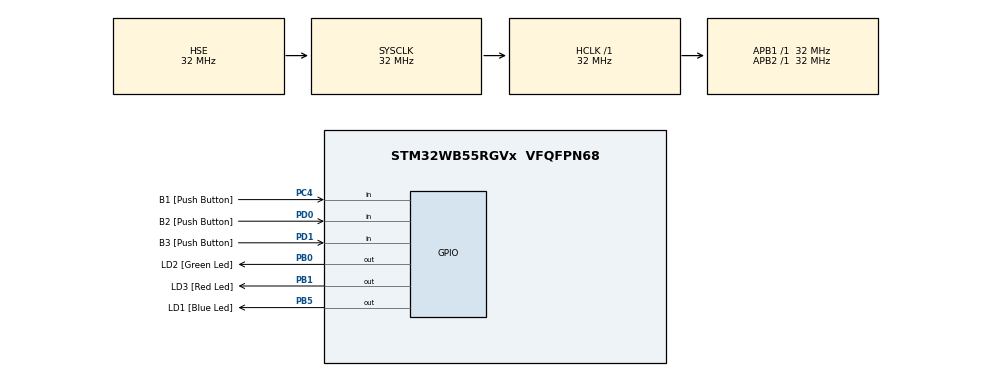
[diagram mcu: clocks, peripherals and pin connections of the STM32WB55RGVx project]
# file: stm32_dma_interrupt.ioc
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Dma.MEMTOMEM.0.Direction=DMA_MEMORY_TO_MEMORY
Dma.MEMTOMEM.0.EventEnable=DISABLE
Dma.MEMTOMEM.0.Instance=DMA1_Channel1
Dma.MEMTOMEM.0.MemDataAlignment=DMA_MDATAALIGN_BYTE
Dma.MEMTOMEM.0.MemInc=DMA_MINC_DISABLE
Dma.MEMTOMEM.0.Mode=DMA_NORMAL
Dma.MEMTOMEM.0.PeriphDataAlignment=DMA_PDATAALIGN_BYTE
Dma.MEMTOMEM.0.PeriphInc=DMA_PINC_DISABLE
Dma.MEMTOMEM.0.Polarity=HAL_DMAMUX_REQ_GEN_RISING
Dma.MEMTOMEM.0.Priority=DMA_PRIORITY_LOW
Dma.MEMTOMEM.0.RequestNumber=1
Dma.MEMTOMEM.0.SignalID=NONE
Dma.MEMTOMEM.0.SyncEnable=DISABLE
Dma.MEMTOMEM.0.SyncPolarity=HAL_DMAMUX_SYNC_NO_EVENT
Dma.MEMTOMEM.0.SyncRequestNumber=1
Dma.MEMTOMEM.0.SyncSignalID=NONE
Dma.Request0=MEMTOMEM
Mcu.Family=STM32WB
Mcu.Name=STM32WB55RGVx
Mcu.Package=VFQFPN68
NVIC.DMA1_Channel1_IRQn=true\:0\:0\:false\:false\:true\:true\:true\:true
NVIC.PriorityGroup=NVIC_PRIORITYGROUP_4
NVIC.RCC_IRQn=true\:0\:0\:false\:false\:true\:true\:false\:true
OSC_IN.Mode=HSE-External-Oscillator
OSC_IN.Signal=RCC_OSC_IN
OSC_OUT.Mode=HSE-External-Oscillator
OSC_OUT.Signal=RCC_OSC_OUT
PA11.Signal=USB_DM
PA12.Signal=USB_DP
PA13.GPIO_Label=JTMS
PA13.Signal=SYS_JTMS-SWDIO
PA14.GPIO_Label=JTCK
PA14.Signal=SYS_JTCK-SWCLK
PB0.GPIO_Label=LD2 [Green Led]
PB0.Signal=GPIO_Output
PB1.GPIO_Label=LD3 [Red Led]
PB1.Signal=GPIO_Output
PB3.GPIO_Label=JTDO
PB3.Signal=SYS_JTDO-SWO
PB5.GPIO_Label=LD1 [Blue Led]
PB5.Signal=GPIO_Output
PB6.GPIO_Label=STLINK_RX
PB6.Signal=USART1_TX
PB7.GPIO_Label=STLINK_TX
PB7.Signal=USART1_RX
PC13.Signal=SYS_WKUP2
PC14-OSC32_IN.Mode=LSE-External-Oscillator
PC14-OSC32_IN.Signal=RCC_OSC32_IN
PC15-OSC32_OUT.Mode=LSE-External-Oscillator
PC15-OSC32_OUT.Signal=RCC_OSC32_OUT
PC4.GPIO_Label=B1 [Push Button]
PC4.Signal=GPIO_Input
PD0.GPIO_Label=B2 [Push Button]
PD0.Signal=GPIO_Input
PD1.GPIO_Label=B3 [Push Button]
PD1.Signal=GPIO_Input
ProjectManager.HeapSize=0x200
ProjectManager.StackSize=0x400
ProjectManager.TargetToolchain=STM32CubeIDE
RCC.ADCFreq_Value=128000000
RCC.AHBFreq_Value=32000000
RCC.APB1Freq_Value=32000000
RCC.APB1TimFreq_Value=32000000
RCC.APB2Freq_Value=32000000
RCC.APB2TimFreq_Value=32000000
RCC.APB3Freq_Value=16000000
RCC.CortexFreq_Value=32000000
RCC.EnbaleCSS=true
RCC.HCLKFreq_Value=32000000
RCC.HSE_VALUE=32000000
RCC.HSI48_VALUE=48000000
RCC.HSI_VALUE=16000000
RCC.MSIClockRange=RCC_MSIRANGE_10
RCC.SMPSCLockSelectionVirtual=RCC_SMPSCLKSOURCE_HSI
RCC.SMPSCLockSelectionVirtualVirtual=RCC_SMPSCLKSOURCE_HSI
RCC.SMPSDivider=1
RCC.SYSCLKFreq_VALUE=32000000
RCC.SYSCLKSource=RCC_SYSCLKSOURCE_HSE
RCC.USBFreq_Value=128000000
RCC.VCOOutputFreq_Value=256000000
board=P-NUCLEO-WB55-NUCLEO

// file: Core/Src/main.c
/* USER CODE BEGIN Header */
/**
  ******************************************************************************
  * @file           : main.c
  * @brief          : Main program body
  ******************************************************************************
  * @attention
  *
  * Copyright (c) 2022 STMicroelectronics.
  * All rights reserved.
  *
  * This software is licensed under terms that can be found in the LICENSE file
  * in the root directory of this software component.
  * If no LICENSE file comes with this software, it is provided AS-IS.
  *
  ******************************************************************************
  */
/* USER CODE END Header */
#include "main.h"

DMA_HandleTypeDef hdma_memtomem_dma1_channel1;

void SystemClock_Config(void);
void PeriphCommonClock_Config(void);
static void MX_GPIO_Init(void);
static void MX_DMA_Init(void);

/* USER CODE BEGIN 0 */
void DMA_IT_GPIOLED(DMA_HandleTypeDef *pDMAHandler);

/* USER CODE END 0 */

int main(void)
{

  /* MCU Configuration--------------------------------------------------------*/

  /* Reset of all peripherals, Initializes the Flash interface and the Systick. */
  HAL_Init();

  /* Configure the system clock */
  SystemClock_Config();

/* Configure the peripherals common clocks */
  PeriphCommonClock_Config();

  /* Initialize all configured peripherals */
  MX_GPIO_Init();
  MX_DMA_Init();
  /* USER CODE BEGIN 2 */
    uint32_t Currentstart;
    uint32_t ledData[2]= {0x000, 0xFFFF};
    HAL_DMA_RegisterCallback(&hdma_memtomem_dma1_channel1, HAL_DMA_XFER_CPLT_CB_ID, &DMA_IT_GPIOLED);
  /* USER CODE END 2 */

  /* Infinite loop */
  while (1)
  {

    /* USER CODE BEGIN 3 */
	  HAL_DMA_Start_IT(&hdma_memtomem_dma1_channel1, (uint32_t) &ledData[0], (uint32_t)&GPIOB->ODR, 2);
	      Currentstart= HAL_GetTick();
	      while( (Currentstart + 500) >= HAL_GetTick());

	      HAL_DMA_Start_IT(&hdma_memtomem_dma1_channel1, (uint32_t) &ledData[1], (uint32_t)&GPIOB->ODR, 2);
	      Currentstart= HAL_GetTick();
	      while( (Currentstart + 500) >= HAL_GetTick());
  }
  /* USER CODE END 3 */
}

void SystemClock_Config(void)
{
  RCC_OscInitTypeDef RCC_OscInitStruct = {0};
  RCC_ClkInitTypeDef RCC_ClkInitStruct = {0};

  /** Configure the main internal regulator output voltage
  */
  __HAL_PWR_VOLTAGESCALING_CONFIG(PWR_REGULATOR_VOLTAGE_SCALE1);

  /** Initializes the RCC Oscillators according to the specified parameters
  * in the RCC_OscInitTypeDef structure.
  */
  RCC_OscInitStruct.OscillatorType = RCC_OSCILLATORTYPE_HSI|RCC_OSCILLATORTYPE_HSE;
  RCC_OscInitStruct.HSEState = RCC_HSE_ON;
  RCC_OscInitStruct.HSIState = RCC_HSI_ON;
  RCC_OscInitStruct.HSICalibrationValue = RCC_HSICALIBRATION_DEFAULT;
  RCC_OscInitStruct.PLL.PLLState = RCC_PLL_NONE;
  if (HAL_RCC_OscConfig(&RCC_OscInitStruct) != HAL_OK)
  {
    Error_Handler();
  }

  /** Configure the SYSCLKSource, HCLK, PCLK1 and PCLK2 clocks dividers
  */
  RCC_ClkInitStruct.ClockType = RCC_CLOCKTYPE_HCLK4|RCC_CLOCKTYPE_HCLK2
                              |RCC_CLOCKTYPE_HCLK|RCC_CLOCKTYPE_SYSCLK
                              |RCC_CLOCKTYPE_PCLK1|RCC_CLOCKTYPE_PCLK2;
  RCC_ClkInitStruct.SYSCLKSource = RCC_SYSCLKSOURCE_HSE;
  RCC_ClkInitStruct.AHBCLKDivider = RCC_SYSCLK_DIV1;
  RCC_ClkInitStruct.APB1CLKDivider = RCC_HCLK_DIV1;
  RCC_ClkInitStruct.APB2CLKDivider = RCC_HCLK_DIV1;
  RCC_ClkInitStruct.AHBCLK2Divider = RCC_SYSCLK_DIV1;
  RCC_ClkInitStruct.AHBCLK4Divider = RCC_SYSCLK_DIV1;

  if (HAL_RCC_ClockConfig(&RCC_ClkInitStruct, FLASH_LATENCY_1) != HAL_OK)
  {
    Error_Handler();
  }

  /** Enables the Clock Security System
  */
  HAL_RCC_EnableCSS();
}

void PeriphCommonClock_Config(void)
{
  RCC_PeriphCLKInitTypeDef PeriphClkInitStruct = {0};

  /** Initializes the peripherals clock
  */
  PeriphClkInitStruct.PeriphClockSelection = RCC_PERIPHCLK_SMPS;
  PeriphClkInitStruct.SmpsClockSelection = RCC_SMPSCLKSOURCE_HSI;
  PeriphClkInitStruct.SmpsDivSelection = RCC_SMPSCLKDIV_RANGE0;

  if (HAL_RCCEx_PeriphCLKConfig(&PeriphClkInitStruct) != HAL_OK)
  {
    Error_Handler();
  }
}

static void MX_DMA_Init(void)
{

  /* DMA controller clock enable */
  __HAL_RCC_DMAMUX1_CLK_ENABLE();
  __HAL_RCC_DMA1_CLK_ENABLE();

  /* Configure DMA request hdma_memtomem_dma1_channel1 on DMA1_Channel1 */
  hdma_memtomem_dma1_channel1.Instance = DMA1_Channel1;
  hdma_memtomem_dma1_channel1.Init.Request = DMA_REQUEST_MEM2MEM;
  hdma_memtomem_dma1_channel1.Init.Direction = DMA_MEMORY_TO_MEMORY;
  hdma_memtomem_dma1_channel1.Init.PeriphInc = DMA_PINC_DISABLE;
  hdma_memtomem_dma1_channel1.Init.MemInc = DMA_MINC_DISABLE;
  hdma_memtomem_dma1_channel1.Init.PeriphDataAlignment = DMA_PDATAALIGN_BYTE;
  hdma_memtomem_dma1_channel1.Init.MemDataAlignment = DMA_MDATAALIGN_BYTE;
  hdma_memtomem_dma1_channel1.Init.Mode = DMA_NORMAL;
  hdma_memtomem_dma1_channel1.Init.Priority = DMA_PRIORITY_LOW;
  if (HAL_DMA_Init(&hdma_memtomem_dma1_channel1) != HAL_OK)
  {
    Error_Handler( );
  }

  /* DMA interrupt init */
  /* DMA1_Channel1_IRQn interrupt configuration */
  HAL_NVIC_SetPriority(DMA1_Channel1_IRQn, 0, 0);
  HAL_NVIC_EnableIRQ(DMA1_Channel1_IRQn);

}

static void MX_GPIO_Init(void)
{
  GPIO_InitTypeDef GPIO_InitStruct = {0};

  /* GPIO Ports Clock Enable */
  __HAL_RCC_GPIOC_CLK_ENABLE();
  __HAL_RCC_GPIOB_CLK_ENABLE();
  __HAL_RCC_GPIOA_CLK_ENABLE();
  __HAL_RCC_GPIOD_CLK_ENABLE();

  /*Configure GPIO pin Output Level */
  HAL_GPIO_WritePin(GPIOB, LD2_Pin|LD3_Pin|LD1_Pin, GPIO_PIN_RESET);

  /*Configure GPIO pin : B1_Pin */
  GPIO_InitStruct.Pin = B1_Pin;
  GPIO_InitStruct.Mode = GPIO_MODE_INPUT;
  GPIO_InitStruct.Pull = GPIO_NOPULL;
  HAL_GPIO_Init(B1_GPIO_Port, &GPIO_InitStruct);

  /*Configure GPIO pins : LD2_Pin LD3_Pin LD1_Pin */
  GPIO_InitStruct.Pin = LD2_Pin|LD3_Pin|LD1_Pin;
  GPIO_InitStruct.Mode = GPIO_MODE_OUTPUT_PP;
  GPIO_InitStruct.Pull = GPIO_NOPULL;
  GPIO_InitStruct.Speed = GPIO_SPEED_FREQ_LOW;
  HAL_GPIO_Init(GPIOB, &GPIO_InitStruct);

  /*Configure GPIO pins : PA11 PA12 */
  GPIO_InitStruct.Pin = GPIO_PIN_11|GPIO_PIN_12;
  GPIO_InitStruct.Mode = GPIO_MODE_AF_PP;
  GPIO_InitStruct.Pull = GPIO_NOPULL;
  GPIO_InitStruct.Speed = GPIO_SPEED_FREQ_LOW;
  GPIO_InitStruct.Alternate = GPIO_AF10_USB;
  HAL_GPIO_Init(GPIOA, &GPIO_InitStruct);

  /*Configure GPIO pins : B2_Pin B3_Pin */
  GPIO_InitStruct.Pin = B2_Pin|B3_Pin;
  GPIO_InitStruct.Mode = GPIO_MODE_INPUT;
  GPIO_InitStruct.Pull = GPIO_NOPULL;
  HAL_GPIO_Init(GPIOD, &GPIO_InitStruct);

  /*Configure GPIO pins : STLINK_RX_Pin STLINK_TX_Pin */
  GPIO_InitStruct.Pin = STLINK_RX_Pin|STLINK_TX_Pin;
  GPIO_InitStruct.Mode = GPIO_MODE_AF_PP;
  GPIO_InitStruct.Pull = GPIO_NOPULL;
  GPIO_InitStruct.Speed = GPIO_SPEED_FREQ_LOW;
  GPIO_InitStruct.Alternate = GPIO_AF7_USART1;
  HAL_GPIO_Init(GPIOB, &GPIO_InitStruct);

}

/* USER CODE BEGIN 4 */
void DMA_IT_GPIOLED(DMA_HandleTypeDef *pDMAHandler)
{
    //HAL_DMA_PollForTransfer(&pDMAHandler, HAL_DMA_FULL_TRANSFER, HAL_MAX_DELAY );
}
/* USER CODE END 4 */

void Error_Handler(void)
{
  __disable_irq();
  while (1)
  {
  }
}
